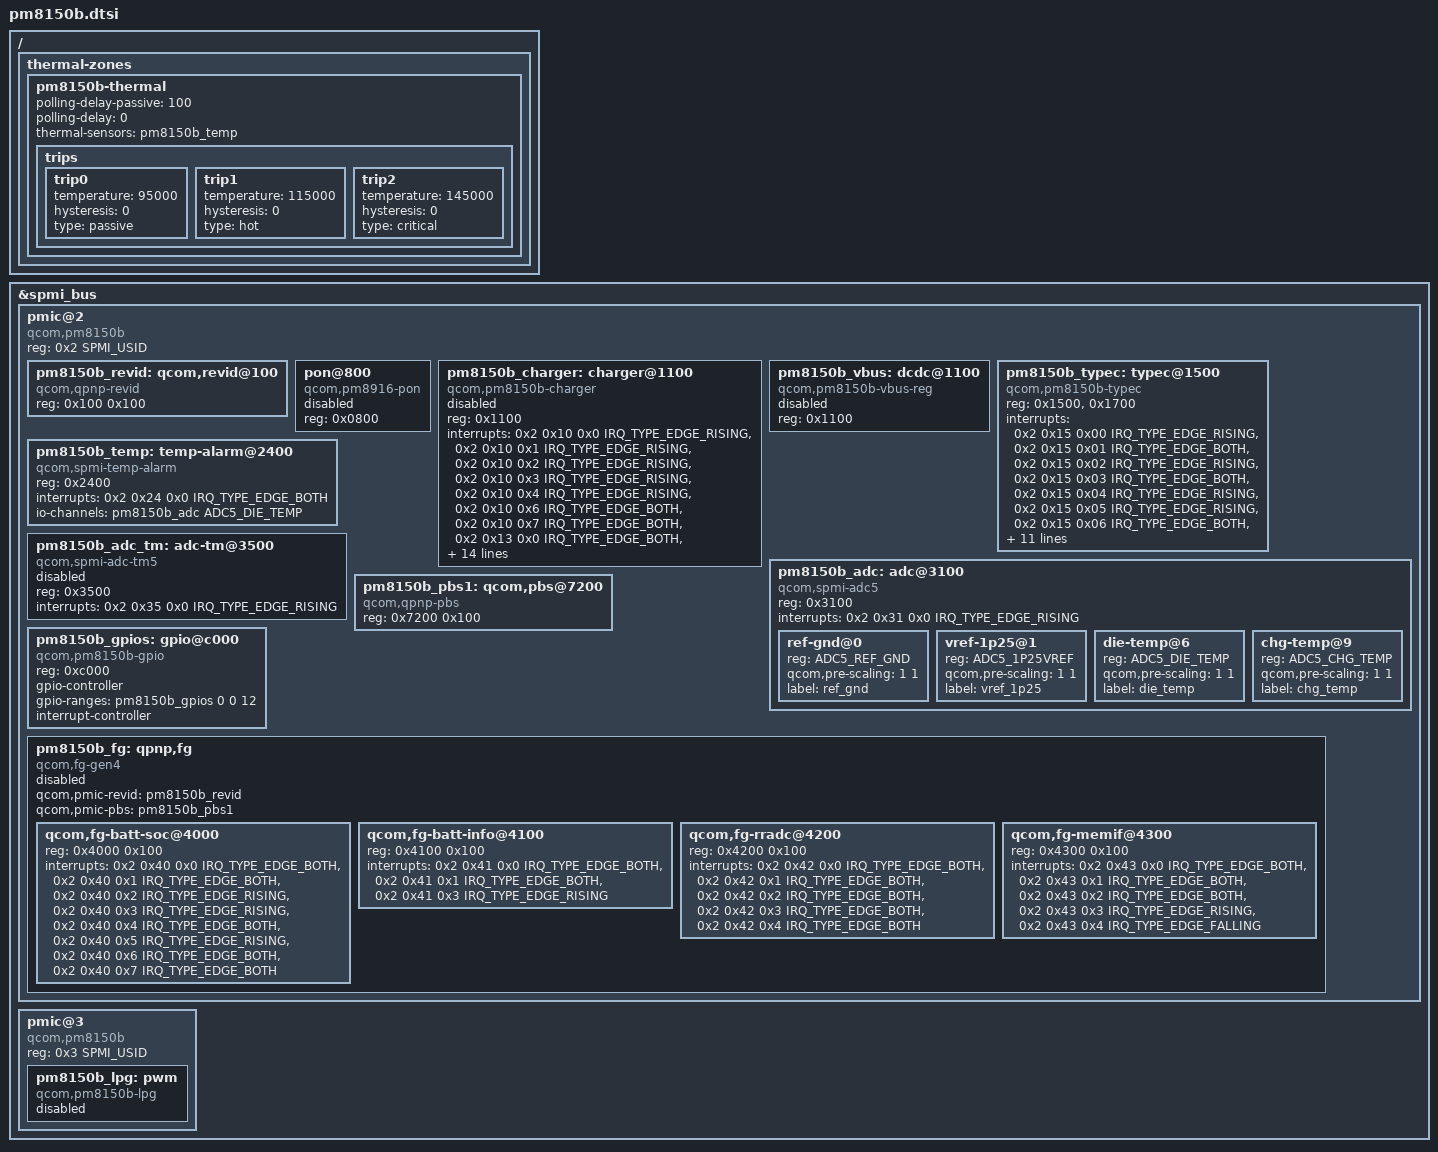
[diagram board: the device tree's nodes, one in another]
// SPDX-License-Identifier: BSD-3-Clause
/*
 * Copyright (c) 2017-2019, The Linux Foundation. All rights reserved.
 * Copyright (c) 2019, Linaro Limited
 */

#include <dt-bindings/iio/qcom,spmi-vadc.h>
#include <dt-bindings/interrupt-controller/irq.h>
#include <dt-bindings/spmi/spmi.h>

/ {
	thermal-zones {
		pm8150b-thermal {
			polling-delay-passive = <100>;
			polling-delay = <0>;

			thermal-sensors = <&pm8150b_temp>;

			trips {
				trip0 {
					temperature = <95000>;
					hysteresis = <0>;
					type = "passive";
				};

				trip1 {
					temperature = <115000>;
					hysteresis = <0>;
					type = "hot";
				};

				trip2 {
					temperature = <145000>;
					hysteresis = <0>;
					type = "critical";
				};
			};
		};
	};
};

&spmi_bus {
	pmic@2 {
		compatible = "qcom,pm8150b", "qcom,spmi-pmic";
		reg = <0x2 SPMI_USID>;
		#address-cells = <1>;
		#size-cells = <0>;

		pm8150b_revid: qcom,revid@100 {
			compatible = "qcom,qpnp-revid";
			reg = <0x100 0x100>;
		};

		pon@800 {
			compatible = "qcom,pm8916-pon";
			reg = <0x0800>;

			status = "disabled";
		};

		pm8150b_charger: charger@1100 {
			compatible = "qcom,pm8150b-charger";
			status = "disabled";
			reg = <0x1100>;
			interrupts =
				<0x2 0x10 0x0 IRQ_TYPE_EDGE_RISING>,
				<0x2 0x10 0x1 IRQ_TYPE_EDGE_RISING>,
				<0x2 0x10 0x2 IRQ_TYPE_EDGE_RISING>,
				<0x2 0x10 0x3 IRQ_TYPE_EDGE_RISING>,
				<0x2 0x10 0x4 IRQ_TYPE_EDGE_RISING>,
				<0x2 0x10 0x6 IRQ_TYPE_EDGE_BOTH>,
				<0x2 0x10 0x7 IRQ_TYPE_EDGE_BOTH>,
				<0x2 0x13 0x0 IRQ_TYPE_EDGE_BOTH>,
				<0x2 0x13 0x1 IRQ_TYPE_EDGE_BOTH>,
				<0x2 0x13 0x2 IRQ_TYPE_EDGE_BOTH>,
				<0x2 0x13 0x3 IRQ_TYPE_EDGE_BOTH>,
				<0x2 0x13 0x4 IRQ_TYPE_EDGE_BOTH>,
				<0x2 0x13 0x5 IRQ_TYPE_EDGE_BOTH>,
				<0x2 0x13 0x6 IRQ_TYPE_EDGE_RISING>,
				<0x2 0x13 0x7 IRQ_TYPE_EDGE_RISING>,
				<0x2 0x14 0x1 IRQ_TYPE_EDGE_BOTH>,
				<0x2 0x14 0x2 IRQ_TYPE_EDGE_BOTH>,
				<0x2 0x14 0x3 IRQ_TYPE_EDGE_BOTH>,
				<0x2 0x14 0x4 IRQ_TYPE_EDGE_BOTH>,
				<0x2 0x14 0x5 IRQ_TYPE_EDGE_BOTH>,
				<0x2 0x14 0x6 IRQ_TYPE_EDGE_BOTH>,
				<0x2 0x14 0x7 IRQ_TYPE_EDGE_BOTH>;

			interrupt-names = "chgr-error",
					  "chg-state-change",
					  "step-chg-state-change",
					  "step-chg-soc-update-fail",
					  "step-chg-soc-update-req",
					  "vph-alarm",
					  "vph-drop-prechg",
					  "usbin-collapse",
					  "usbin-vashdn",
					  "usbin-uv",
					  "usbin-ov",
					  "usbin-plugin",
					  "usbin-revi-change",
					  "usbin-src-change",
					  "usbin-icl-change",
					  "dcin-vashdn",
					  "dcin-uv",
					  "dcin-ov",
					  "dcin-plugin",
					  "dcin-revi",
					  "dcin-pon",
					  "dcin-en";
		};
	
		pm8150b_vbus: dcdc@1100 {
			compatible = "qcom,pm8150b-vbus-reg";
			status = "disabled";
			reg = <0x1100>;
		};

		pm8150b_typec: typec@1500 {
			compatible = "qcom,pm8150b-typec";
			reg = <0x1500>,
			      <0x1700>;
			interrupts = <0x2 0x15 0x00 IRQ_TYPE_EDGE_RISING>,
				     <0x2 0x15 0x01 IRQ_TYPE_EDGE_BOTH>,
				     <0x2 0x15 0x02 IRQ_TYPE_EDGE_RISING>,
				     <0x2 0x15 0x03 IRQ_TYPE_EDGE_BOTH>,
				     <0x2 0x15 0x04 IRQ_TYPE_EDGE_RISING>,
				     <0x2 0x15 0x05 IRQ_TYPE_EDGE_RISING>,
				     <0x2 0x15 0x06 IRQ_TYPE_EDGE_BOTH>,
				     <0x2 0x15 0x07 IRQ_TYPE_EDGE_RISING>,
				     <0x2 0x17 0x00 IRQ_TYPE_EDGE_RISING>,
				     <0x2 0x17 0x01 IRQ_TYPE_EDGE_RISING>,
				     <0x2 0x17 0x02 IRQ_TYPE_EDGE_RISING>,
				     <0x2 0x17 0x03 IRQ_TYPE_EDGE_RISING>,
				     <0x2 0x17 0x04 IRQ_TYPE_EDGE_RISING>,
				     <0x2 0x17 0x05 IRQ_TYPE_EDGE_RISING>,
				     <0x2 0x17 0x06 IRQ_TYPE_EDGE_RISING>,
				     <0x2 0x17 0x07 IRQ_TYPE_EDGE_RISING>;
			interrupt-names = "or-rid-detect-change",
					  "vpd-detect",
					  "cc-state-change",
					  "vconn-oc",
					  "vbus-change",
					  "attach-detach",
					  "legacy-cable-detect",
					  "try-snk-src-detect",
					  "sig-tx",
					  "sig-rx",
					  "msg-tx",
					  "msg-rx",
					  "msg-tx-failed",
					  "msg-tx-discarded",
					  "msg-rx-discarded",
					  "fr-swap";
			vdd-pdphy-supply = <&vreg_l2a_3p1>;
			vdd-vbus-supply = <&pm8150b_vbus>;
		};

		pm8150b_temp: temp-alarm@2400 {
			compatible = "qcom,spmi-temp-alarm";
			reg = <0x2400>;
			interrupts = <0x2 0x24 0x0 IRQ_TYPE_EDGE_BOTH>;
			io-channels = <&pm8150b_adc ADC5_DIE_TEMP>;
			io-channel-names = "thermal";
			#thermal-sensor-cells = <0>;
		};

		pm8150b_adc: adc@3100 {
			compatible = "qcom,spmi-adc5";
			reg = <0x3100>;
			#address-cells = <1>;
			#size-cells = <0>;
			#io-channel-cells = <1>;
			interrupts = <0x2 0x31 0x0 IRQ_TYPE_EDGE_RISING>;

			ref-gnd@0 {
				reg = <ADC5_REF_GND>;
				qcom,pre-scaling = <1 1>;
				label = "ref_gnd";
			};

			vref-1p25@1 {
				reg = <ADC5_1P25VREF>;
				qcom,pre-scaling = <1 1>;
				label = "vref_1p25";
			};

			die-temp@6 {
				reg = <ADC5_DIE_TEMP>;
				qcom,pre-scaling = <1 1>;
				label = "die_temp";
			};

			chg-temp@9 {
				reg = <ADC5_CHG_TEMP>;
				qcom,pre-scaling = <1 1>;
				label = "chg_temp";
			};
		};

		pm8150b_adc_tm: adc-tm@3500 {
			compatible = "qcom,spmi-adc-tm5";
			reg = <0x3500>;
			interrupts = <0x2 0x35 0x0 IRQ_TYPE_EDGE_RISING>;
			#thermal-sensor-cells = <1>;
			#address-cells = <1>;
			#size-cells = <0>;
			status = "disabled";
		};

		pm8150b_pbs1: qcom,pbs@7200 {
			compatible = "qcom,qpnp-pbs";
			reg = <0x7200 0x100>;
		};

		pm8150b_gpios: gpio@c000 {
			compatible = "qcom,pm8150b-gpio", "qcom,spmi-gpio";
			reg = <0xc000>;
			gpio-controller;
			gpio-ranges = <&pm8150b_gpios 0 0 12>;
			#gpio-cells = <2>;
			interrupt-controller;
			#interrupt-cells = <2>;
		};

		pm8150b_fg: qpnp,fg {
			compatible = "qcom,fg-gen4";
			#address-cells = <1>;
			#size-cells = <1>;
			qcom,pmic-revid = <&pm8150b_revid>;
			qcom,pmic-pbs = <&pm8150b_pbs1>;
			status = "disabled";

			qcom,fg-batt-soc@4000 {
				status = "okay";
				reg = <0x4000 0x100>;
				interrupts = <0x2 0x40 0x0 IRQ_TYPE_EDGE_BOTH>,
					     <0x2 0x40 0x1 IRQ_TYPE_EDGE_BOTH>,
					     <0x2 0x40 0x2
							IRQ_TYPE_EDGE_RISING>,
					     <0x2 0x40 0x3
							IRQ_TYPE_EDGE_RISING>,
					     <0x2 0x40 0x4 IRQ_TYPE_EDGE_BOTH>,
					     <0x2 0x40 0x5
							IRQ_TYPE_EDGE_RISING>,
					     <0x2 0x40 0x6 IRQ_TYPE_EDGE_BOTH>,
					     <0x2 0x40 0x7 IRQ_TYPE_EDGE_BOTH>;
				interrupt-names = "soc-update",
						  "soc-ready",
						  "bsoc-delta",
						  "msoc-delta",
						  "msoc-low",
						  "msoc-empty",
						  "msoc-high",
						  "msoc-full";
			};

			qcom,fg-batt-info@4100 {
				status = "okay";
				reg = <0x4100 0x100>;
				interrupts = <0x2 0x41 0x0 IRQ_TYPE_EDGE_BOTH>,
					     <0x2 0x41 0x1 IRQ_TYPE_EDGE_BOTH>,
					     <0x2 0x41 0x3
							IRQ_TYPE_EDGE_RISING>;
				interrupt-names = "vbatt-low",
						  "vbatt-pred-delta",
						  "esr-delta";
			};

			qcom,fg-rradc@4200 {
				status = "okay";
				reg = <0x4200 0x100>;
				interrupts = <0x2 0x42 0x0 IRQ_TYPE_EDGE_BOTH>,
					     <0x2 0x42 0x1 IRQ_TYPE_EDGE_BOTH>,
					     <0x2 0x42 0x2 IRQ_TYPE_EDGE_BOTH>,
					     <0x2 0x42 0x3 IRQ_TYPE_EDGE_BOTH>,
					     <0x2 0x42 0x4 IRQ_TYPE_EDGE_BOTH>;
				interrupt-names = "batt-missing",
						  "batt-id",
						  "batt-temp-delta",
						  "batt-temp-hot",
						  "batt-temp-cold";
			};

			qcom,fg-memif@4300 {
				status = "okay";
				reg = <0x4300 0x100>;
				interrupts = <0x2 0x43 0x0 IRQ_TYPE_EDGE_BOTH>,
					     <0x2 0x43 0x1 IRQ_TYPE_EDGE_BOTH>,
					     <0x2 0x43 0x2 IRQ_TYPE_EDGE_BOTH>,
					     <0x2 0x43 0x3
							IRQ_TYPE_EDGE_RISING>,
					     <0x2 0x43 0x4
							IRQ_TYPE_EDGE_FALLING>;
				interrupt-names = "ima-rdy",
						  "ima-xcp",
						  "dma-xcp",
						  "dma-grant",
						  "mem-attn";
			};
		};
	};

	pmic@3 {
		compatible = "qcom,pm8150b", "qcom,spmi-pmic";
		reg = <0x3 SPMI_USID>;
		#address-cells = <1>;
		#size-cells = <0>;

		pm8150b_lpg: pwm {
			compatible = "qcom,pm8150b-lpg";

			#address-cells = <1>;
			#size-cells = <0>;
			#pwm-cells = <2>;

			status = "disabled";
		};
	};
};
